# braiins register map
Vendor: Braiins Systems s.r.o.; Series: S9; File version: 0.2.0
S9 I/O
Registers are 32-bit, read-only, reset 0x0 unless marked. A register's access mark holds for its fields unless they carry their own. Offsets are from the block's base; lines under a group give offsets from that group; [hi:lo] are bit positions; {n}, {i} and the like mark numbered series; 'fields as' and 'values as' point back to an identical list; <NAME> marks a mode.

## Memory map
0x00000000 COMMON size 0x1C — Hashing Chain I/O module, common and config registers
0x00000000 COMMAND size 0x10 — Hashing Chain I/O module, command FIFOs
0x00000000 WORKRX size 0x10 — Hashing Chain I/O module, reception FIFO
0x00000000 WORKTX size 0x18 — Hashing Chain I/O module, transmit FIFO
0x00000000 FAN_CTRL size 0x14 — Braiins Fan Controller v0.1
0x00000000 GLITCH_MONITOR size 0x80 — Braiins AXI Glitch Monitor v1.0

## COMMON — Hashing Chain I/O module, common and config registers
Base 0x00000000
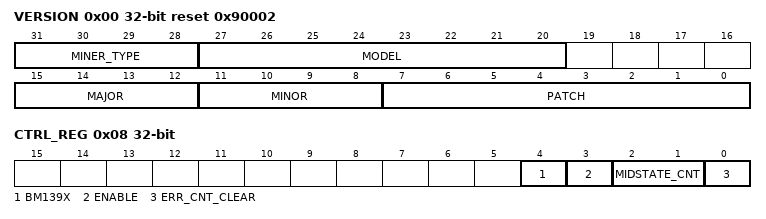
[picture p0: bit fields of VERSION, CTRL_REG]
0x00 VERSION reset 0x90002 — IP Core Version Register
  [31:28] MINER_TYPE
    0=Antminer
  [27:20] MODEL — IP core model
    9=S9
  [15:12] MAJOR — IP core major version
  [11:8] MINOR — IP core minor version
  [7:0] PATCH — IP core patch version
0x04 BUILD_ID
0x08 CTRL_REG rw (reset mask 0xF) — Control Register
  [4] BM139X — Enable support for chips BM1391, BM1397
  [3] ENABLE — Enable of IP core
  [2:1] MIDSTATE_CNT — Number of midstates per work
    0=one; 1=two; 2=four
  [0] ERR_CNT_CLEAR wo — Clear error counter
0x0C STAT_REG — Status Register - reserved
0x10 BAUD_REG rw — Baudrate Divisor Register
0x14 WORK_TIME rw reset 0x1 — Work Time Delay Register
0x18 ERR_COUNTER — Error Counter Register

## COMMAND — Hashing Chain I/O module, command FIFOs
Base 0x00000000
0x00 CMD_RX_FIFO — Command Receive Interface FIFO
0x04 CMD_TX_FIFO wo — Command Transmit Interface FIFO
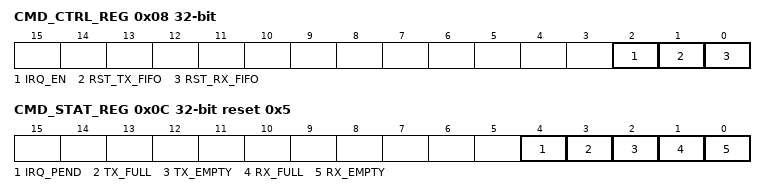
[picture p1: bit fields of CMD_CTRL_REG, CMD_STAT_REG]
0x08 CMD_CTRL_REG rw — Command Control Register
  [2] IRQ_EN — Enable interrupt for Command Receive FIFO
  [1] RST_TX_FIFO wo — Reset/clear Command Transmit FIFO
  [0] RST_RX_FIFO wo — Reset/clear Command Receive FIFO
0x0C CMD_STAT_REG reset 0x5 — Command Status Register
  [4] IRQ_PEND — Interrupt pending for Command Receive FIFO
  [3] TX_FULL — Command Interface Transmit FIFO Full
  [2] TX_EMPTY — Command Interface Transmit FIFO Empty
  [1] RX_FULL — Command Interface Receive FIFO Full
  [0] RX_EMPTY — Command Interface Receive FIFO Empty

## WORKRX — Hashing Chain I/O module, reception FIFO
Base 0x00000000
0x00 WORK_RX_FIFO — Work Receive Interface FIFO
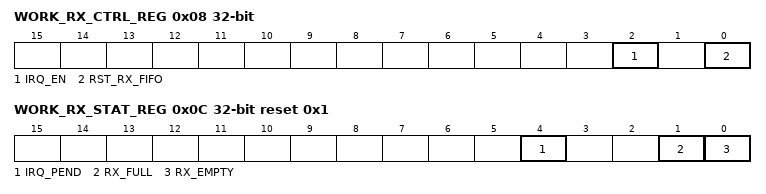
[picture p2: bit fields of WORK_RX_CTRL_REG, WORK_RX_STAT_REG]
0x08 WORK_RX_CTRL_REG rw — Work Receive Control Register
  [2] IRQ_EN — Enable interrupt for Work Receive FIFO
  [0] RST_RX_FIFO wo — Reset/clear Work Receive FIFO
0x0C WORK_RX_STAT_REG reset 0x1 — Work Receive Status Register
  [4] IRQ_PEND — Interrupt pending for Work Receive FIFO
  [1] RX_FULL — Work Interface Receive FIFO Full
  [0] RX_EMPTY — Work Interface Receive FIFO Empty

## WORKTX — Hashing Chain I/O module, transmit FIFO
Base 0x00000000
0x04 WORK_TX_FIFO wo — Work Transmit Interface FIFO
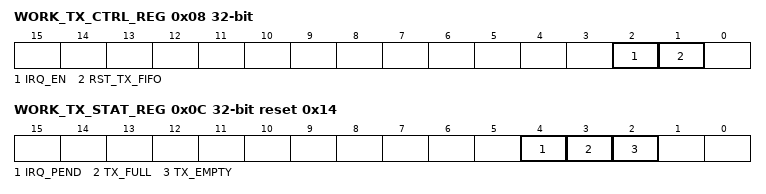
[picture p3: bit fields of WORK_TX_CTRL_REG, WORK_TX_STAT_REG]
0x08 WORK_TX_CTRL_REG rw — Work Transmit Control Register
  [2] IRQ_EN — Enable interrupt for Work Transmit FIFO
  [1] RST_TX_FIFO wo — Reset/clear Work Transmit FIFO
0x0C WORK_TX_STAT_REG reset 0x14 — Work Transmit Status Register
  [4] IRQ_PEND — Interrupt pending for Work Transmit FIFO
  [3] TX_FULL — Work Interface Transmit FIFO Full
  [2] TX_EMPTY — Work Interface Transmit FIFO Empty
0x10 WORK_TX_IRQ_THR rw — Work Transmit IRQ Threshold
0x14 WORK_TX_LAST_ID — Work Transmit Last Work ID

## FAN_CTRL — Braiins Fan Controller v0.1
Base 0x00000000
{0x0+4i} FAN[{i}]_RPS (i=0..3) — Fan Rotation Speed (in revolutions per second)
0x10 FAN_PWM 8-bit rw — PWM Duty Cycle Register

## GLITCH_MONITOR — Braiins AXI Glitch Monitor v1.0
Base 0x00000000
0x00 CTRL_REG rw — Control Register
  [0] CNT_CLEAR wo — Clear all counters
{0x10+8i} CH[{i}]_CNT (i=0..13) — Channel Glitch Counter
{0x14+8i} CH[{i}]_WIDTH (i=0..13) — Channel Last Glitch Width

## Licence text in the file
GPL, all free

## Notices in the file
Copyright (C) 2019  Braiins Systems s.r.o.  All rights reserved.
